# ESP32-P4 register map
Vendor: ESPRESSIF SYSTEMS (SHANGHAI) CO., LTD.; Series: ESP32 P-Series; File version: 2
CPU: RV32IMAFC r0p0, little endian, no MPU, FPU, 0 interrupt priority bits
Address unit: 32 bits
Registers are 32-bit, read-write, reset 0x0 unless marked. A register's access mark holds for its fields unless they carry their own. Offsets are from the block's base; [hi:lo] are bit positions; {n}, {i} and the like mark numbered series.

## ADC — ADC (Analog to Digital Converter)
Base 0x500DE000
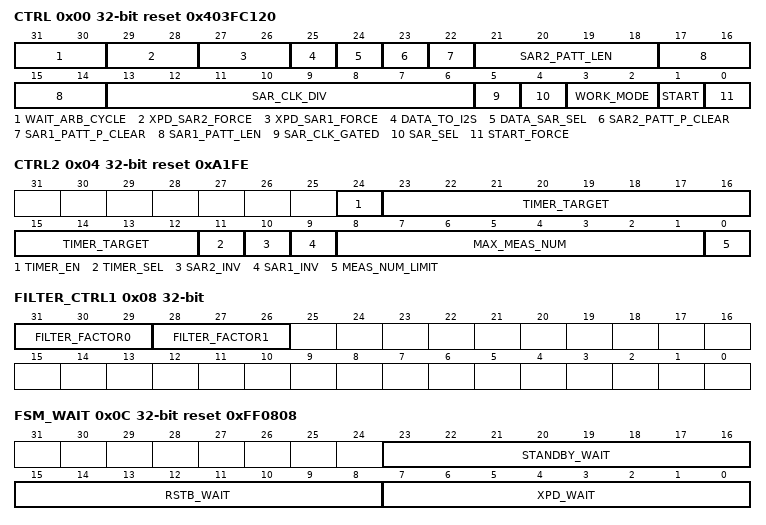
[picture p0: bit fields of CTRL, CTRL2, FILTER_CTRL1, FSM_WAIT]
0x00 CTRL reset 0x403FC120 — Register
  [31:30] WAIT_ARB_CYCLE — wait arbit signal stable after sar_done
  [29:28] XPD_SAR2_FORCE — force option to xpd sar2 blocks
  [27:26] XPD_SAR1_FORCE — force option to xpd sar1 blocks
  [25] DATA_TO_I2S — 1: I2S input data is from SAR ADC (for DMA), 0: I2S input data is from GPIO matrix
  [24] DATA_SAR_SEL — 1: sar_sel will be coded by the MSB of the 16-bit output data, in this case the resolution should not be larger than 11 bits.
  [23] SAR2_PATT_P_CLEAR — clear the pointer of pattern table for DIG ADC2 CTRL
  [22] SAR1_PATT_P_CLEAR — clear the pointer of pattern table for DIG ADC1 CTRL
  [21:18] SAR2_PATT_LEN — 0 ~ 15 means length 1 ~ 16
  [17:14] SAR1_PATT_LEN — 0 ~ 15 means length 1 ~ 16
  [13:6] SAR_CLK_DIV — SAR clock divider
  [5] SAR_CLK_GATED — need_des
  [4] SAR_SEL — 0: SAR1, 1: SAR2, only work for single SAR mode
  [3:2] WORK_MODE — 0: single mode, 1: double mode, 2: alternate mode
  [1] START — need_des
  [0] START_FORCE — need_des
0x04 CTRL2 reset 0xA1FE — Register
  [24] TIMER_EN — to enable saradc timer trigger
  [23:12] TIMER_TARGET — to set saradc timer target
  [11] TIMER_SEL — 1: select saradc timer 0: i2s_ws trigger
  [10] SAR2_INV — 1: data to DIG ADC2 CTRL is inverted, otherwise not
  [9] SAR1_INV — 1: data to DIG ADC1 CTRL is inverted, otherwise not
  [8:1] MAX_MEAS_NUM — max conversion number
  [0] MEAS_NUM_LIMIT — need_des
0x08 FILTER_CTRL1 — Register
  [31:29] FILTER_FACTOR0 — need_des
  [28:26] FILTER_FACTOR1 — need_des
0x0C FSM_WAIT reset 0xFF0808 — Register
  [23:16] STANDBY_WAIT — need_des
  [15:8] RSTB_WAIT — need_des
  [7:0] XPD_WAIT — need_des
0x10 SAR1_STATUS ro — Register
0x14 SAR2_STATUS ro — Register
0x18 SAR1_PATT_TAB1 — Register
  [23:0] SAR1_PATT_TAB1 — item 0 ~ 3 for pattern table 1 (each item one byte)
{0x14+4i} SAR1_PATT_TAB{i} (i=2..4) — Register
  [23:0] SAR1_PATT_TAB{i} — Item {4i-4} ~ {4i-1} for pattern table 1 (each item one byte)
0x28 SAR2_PATT_TAB1 — Register
  [23:0] SAR2_PATT_TAB1 — item 0 ~ 3 for pattern table 2 (each item one byte)
{0x24+4i} SAR2_PATT_TAB{i} (i=2..4) — Register
  [23:0] SAR2_PATT_TAB{i} — Item {4i-4} ~ {4i-1} for pattern table 2 (each item one byte)
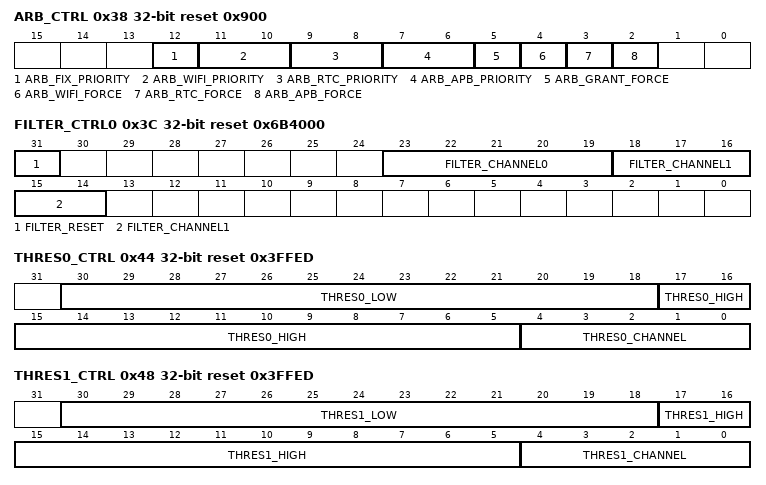
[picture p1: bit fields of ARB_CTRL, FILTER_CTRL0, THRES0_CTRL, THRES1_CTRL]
0x38 ARB_CTRL reset 0x900 — Register
  [12] ARB_FIX_PRIORITY — adc2 arbiter uses fixed priority
  [11:10] ARB_WIFI_PRIORITY — Set adc2 arbiter wifi priority
  [9:8] ARB_RTC_PRIORITY — Set adc2 arbiter rtc priority
  [7:6] ARB_APB_PRIORITY — Set adc2 arbiterapb priority
  [5] ARB_GRANT_FORCE — adc2 arbiter force grant
  [4] ARB_WIFI_FORCE — adc2 arbiter force to enable wifi controller
  [3] ARB_RTC_FORCE — adc2 arbiter force to enable rtc controller
  [2] ARB_APB_FORCE — adc2 arbiter force to enableapb controller
0x3C FILTER_CTRL0 reset 0x6B4000 — Register
  [31] FILTER_RESET — enable apb_adc1_filter
  [23:19] FILTER_CHANNEL0 — apb_adc1_filter_factor
  [18:14] FILTER_CHANNEL1 — need_des
0x40 SAR1_DATA_STATUS ro — Register
  [16:0] APB_SARADC1_DATA — need_des
0x44 THRES0_CTRL reset 0x3FFED — Register
  [30:18] THRES0_LOW — saradc1's thres0 monitor thres
  [17:5] THRES0_HIGH — saradc1's thres0 monitor thres
  [4:0] THRES0_CHANNEL — need_des
0x48 THRES1_CTRL reset 0x3FFED — Register
  [30:18] THRES1_LOW — saradc1's thres0 monitor thres
  [17:5] THRES1_HIGH — saradc1's thres0 monitor thres
  [4:0] THRES1_CHANNEL — need_des
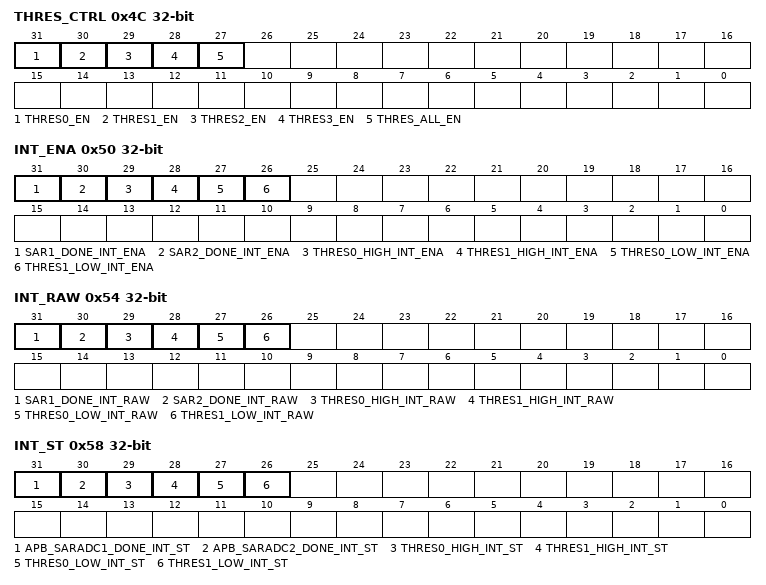
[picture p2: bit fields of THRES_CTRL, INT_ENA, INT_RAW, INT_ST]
0x4C THRES_CTRL — Register
  [31-n] THRES{n}_EN (n=0..3) — need_des
  [27] THRES_ALL_EN — need_des
0x50 INT_ENA — Register
  [31] SAR1_DONE_INT_ENA — need_des
  [30] SAR2_DONE_INT_ENA — need_des
  [29] THRES0_HIGH_INT_ENA — need_des
  [28] THRES1_HIGH_INT_ENA — need_des
  [27] THRES0_LOW_INT_ENA — need_des
  [26] THRES1_LOW_INT_ENA — need_des
0x54 INT_RAW — Register
  [31] SAR1_DONE_INT_RAW — need_des
  [30] SAR2_DONE_INT_RAW — need_des
  [29] THRES0_HIGH_INT_RAW — need_des
  [28] THRES1_HIGH_INT_RAW — need_des
  [27] THRES0_LOW_INT_RAW — need_des
  [26] THRES1_LOW_INT_RAW — need_des
0x58 INT_ST ro — Register
  [31] APB_SARADC1_DONE_INT_ST — need_des
  [30] APB_SARADC2_DONE_INT_ST — need_des
  [29] THRES0_HIGH_INT_ST — need_des
  [28] THRES1_HIGH_INT_ST — need_des
  [27] THRES0_LOW_INT_ST — need_des
  [26] THRES1_LOW_INT_ST — need_des
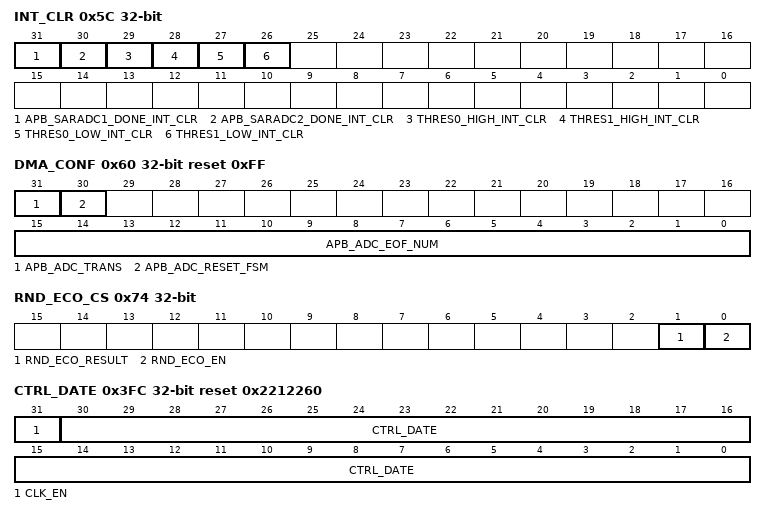
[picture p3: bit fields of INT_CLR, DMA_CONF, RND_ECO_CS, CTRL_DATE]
0x5C INT_CLR wo — Register
  [31] APB_SARADC1_DONE_INT_CLR — need_des
  [30] APB_SARADC2_DONE_INT_CLR — need_des
  [29] THRES0_HIGH_INT_CLR — need_des
  [28] THRES1_HIGH_INT_CLR — need_des
  [27] THRES0_LOW_INT_CLR — need_des
  [26] THRES1_LOW_INT_CLR — need_des
0x60 DMA_CONF reset 0xFF — Register
  [31] APB_ADC_TRANS — enable apb_adc use spi_dma
  [30] APB_ADC_RESET_FSM — reset_apb_adc_state
  [15:0] APB_ADC_EOF_NUM — the dma_in_suc_eof gen when sample cnt = spi_eof_num
0x64 SAR2_DATA_STATUS ro — Register
  [16:0] APB_SARADC2_DATA — need_des
0x68 CALI reset 0x8000 — Register
  [16:0] CFG — need_des
0x6C RND_ECO_LOW — Register
0x70 RND_ECO_HIGH reset 0xFFFFFFFF — Register
0x74 RND_ECO_CS access per field — Register
  [1] RND_ECO_RESULT ro — need_des
  [0] RND_ECO_EN rw — need_des
0x3FC CTRL_DATE reset 0x2212260 — Register
  [31] CLK_EN — need_des
  [30:0] CTRL_DATE — need_des

## Notices in the file
Copyright 2024 Espressif Systems (Shanghai) PTE LTD
Licensed under the Apache License, Version 2.0 (the "License");
you may not use this file except in compliance with the License.
You may obtain a copy of the License at
http://www.apache.org/licenses/LICENSE-2.0
Unless required by applicable law or agreed to in writing, software
distributed under the License is distributed on an "AS IS" BASIS,
WITHOUT WARRANTIES OR CONDITIONS OF ANY KIND, either express or implied.
See the License for the specific language governing permissions and
limitations under the License.
